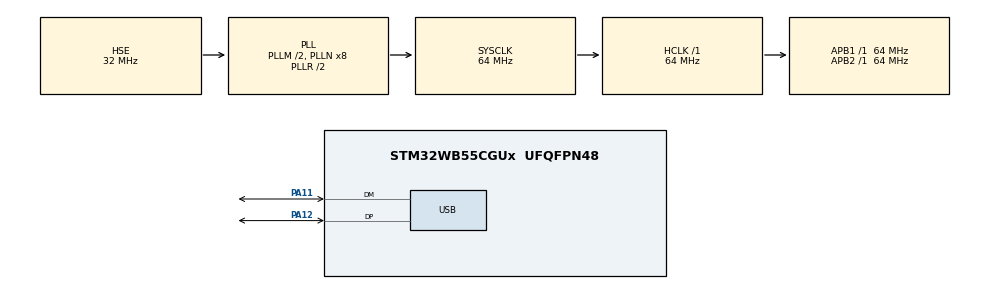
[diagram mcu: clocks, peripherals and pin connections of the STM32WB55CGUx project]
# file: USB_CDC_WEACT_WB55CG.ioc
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Mcu.Family=STM32WB
Mcu.Name=STM32WB55CGUx
Mcu.Package=UFQFPN48
NVIC.PriorityGroup=NVIC_PRIORITYGROUP_4
NVIC.USB_LP_IRQn=true\:0\:0\:false\:false\:true\:false\:true\:true
OSC_IN.Mode=HSE-External-Clock-Source
OSC_IN.Signal=RCC_OSC_IN
PA11.Mode=Device
PA11.Signal=USB_DM
PA12.Mode=Device
PA12.Signal=USB_DP
ProjectManager.HeapSize=0x200
ProjectManager.StackSize=0x400
ProjectManager.TargetToolchain=STM32CubeIDE
RCC.ADCFreq_Value=48000000
RCC.AHB2CLKDivider=RCC_SYSCLK_DIV2
RCC.AHBFreq_Value=64000000
RCC.APB1Freq_Value=64000000
RCC.APB1TimFreq_Value=64000000
RCC.APB2Freq_Value=64000000
RCC.APB2TimFreq_Value=64000000
RCC.APB3Freq_Value=16000000
RCC.CK48CLockSelection=RCC_USBCLKSOURCE_HSI48
RCC.Cortex2_Div=SYSTICK_CLKSOURCE_HCLK_DIV8
RCC.CortexFreq_Value=64000000
RCC.HCLKFreq_Value=64000000
RCC.HSE_VALUE=32000000
RCC.HSI48_VALUE=48000000
RCC.HSI_VALUE=16000000
RCC.LSE_VALUE=32768
RCC.PLLM=RCC_PLLM_DIV2
RCC.PLLSAI1N=6
RCC.PLLSourceVirtual=RCC_PLLSOURCE_HSE
RCC.SYSCLKFreq_VALUE=64000000
RCC.SYSCLKSource=RCC_SYSCLKSOURCE_PLLCLK
RCC.USBFreq_Value=48000000
RCC.VCOOutputFreq_Value=128000000
USB_DEVICE.CLASS_NAME_FS=CDC
USB_DEVICE.VirtualMode=Cdc
USB_DEVICE.VirtualModeFS=Cdc_FS
VP_MEMORYMAP_VS_MEMORYMAP.Mode=CurAppReg
VP_USB_DEVICE_VS_USB_DEVICE_CDC_FS.Mode=CDC_FS
board=custom

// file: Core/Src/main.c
/* USER CODE BEGIN Header */
/**
  ******************************************************************************
  * @file           : main.c
  * @brief          : Main program body
  ******************************************************************************
  * @attention
  *
  * Copyright (c) 2026 STMicroelectronics.
  * All rights reserved.
  *
  * This software is licensed under terms that can be found in the LICENSE file
  * in the root directory of this software component.
  * If no LICENSE file comes with this software, it is provided AS-IS.
  *
  ******************************************************************************
  */
/* USER CODE END Header */
#include "main.h"
#include "usb_device.h"

/* USER CODE BEGIN Includes */
#include "cdc_uart.h"
#include <stdio.h>
#include <string.h>
/* USER CODE END Includes */

/* USER CODE BEGIN PV */
CDC_HandleTypeDef hcdc;             /* user-visible ring-buffer state */
static char line_buf[128];  /* CDC_ReadLine fills this */
/* USER CODE END PV */

void SystemClock_Config(void);
void PeriphCommonClock_Config(void);
static void MX_GPIO_Init(void);

int main(void)
{

  /* MCU Configuration--------------------------------------------------------*/

  /* Reset of all peripherals, Initializes the Flash interface and the Systick. */
  HAL_Init();

  /* Configure the system clock */
  SystemClock_Config();

  /* Configure the peripherals common clocks */
  PeriphCommonClock_Config();

  /* Initialize all configured peripherals */
  MX_GPIO_Init();
  MX_USB_Device_Init();
  /* USER CODE BEGIN 2 */
  CDC_Init(&hcdc);
  /* USER CODE END 2 */

  /* Infinite loop */
  while (1)
  {

    /* USER CODE BEGIN 3 */

    /* --- Read one line at a time, then echo ------------------------- */
    if (CDC_ReadLine(&hcdc, line_buf, sizeof(line_buf)) == CDC_OK) {
      CDC_Printf(&hcdc, "Echo> %s\r\n", line_buf);
    }

    HAL_Delay(5);
  }
  /* USER CODE END 3 */
}

void SystemClock_Config(void)
{
  RCC_OscInitTypeDef RCC_OscInitStruct = {0};
  RCC_ClkInitTypeDef RCC_ClkInitStruct = {0};

  /** Configure the main internal regulator output voltage
  */
  __HAL_PWR_VOLTAGESCALING_CONFIG(PWR_REGULATOR_VOLTAGE_SCALE1);

  /** Initializes the RCC Oscillators according to the specified parameters
  * in the RCC_OscInitTypeDef structure.
  */
  RCC_OscInitStruct.OscillatorType = RCC_OSCILLATORTYPE_HSI48|RCC_OSCILLATORTYPE_HSI
                              |RCC_OSCILLATORTYPE_HSE;
  RCC_OscInitStruct.HSEState = RCC_HSE_ON;
  RCC_OscInitStruct.HSIState = RCC_HSI_ON;
  RCC_OscInitStruct.HSI48State = RCC_HSI48_ON;
  RCC_OscInitStruct.HSICalibrationValue = RCC_HSICALIBRATION_DEFAULT;
  RCC_OscInitStruct.PLL.PLLState = RCC_PLL_ON;
  RCC_OscInitStruct.PLL.PLLSource = RCC_PLLSOURCE_HSE;
  RCC_OscInitStruct.PLL.PLLM = RCC_PLLM_DIV2;
  RCC_OscInitStruct.PLL.PLLN = 8;
  RCC_OscInitStruct.PLL.PLLP = RCC_PLLP_DIV2;
  RCC_OscInitStruct.PLL.PLLR = RCC_PLLR_DIV2;
  RCC_OscInitStruct.PLL.PLLQ = RCC_PLLQ_DIV2;
  if (HAL_RCC_OscConfig(&RCC_OscInitStruct) != HAL_OK)
  {
    Error_Handler();
  }

  /** Configure the SYSCLKSource, HCLK, PCLK1 and PCLK2 clocks dividers
  */
  RCC_ClkInitStruct.ClockType = RCC_CLOCKTYPE_HCLK4|RCC_CLOCKTYPE_HCLK2
                              |RCC_CLOCKTYPE_HCLK|RCC_CLOCKTYPE_SYSCLK
                              |RCC_CLOCKTYPE_PCLK1|RCC_CLOCKTYPE_PCLK2;
  RCC_ClkInitStruct.SYSCLKSource = RCC_SYSCLKSOURCE_PLLCLK;
  RCC_ClkInitStruct.AHBCLKDivider = RCC_SYSCLK_DIV1;
  RCC_ClkInitStruct.APB1CLKDivider = RCC_HCLK_DIV1;
  RCC_ClkInitStruct.APB2CLKDivider = RCC_HCLK_DIV1;
  RCC_ClkInitStruct.AHBCLK2Divider = RCC_SYSCLK_DIV2;
  RCC_ClkInitStruct.AHBCLK4Divider = RCC_SYSCLK_DIV1;

  if (HAL_RCC_ClockConfig(&RCC_ClkInitStruct, FLASH_LATENCY_3) != HAL_OK)
  {
    Error_Handler();
  }
}

void PeriphCommonClock_Config(void)
{
  RCC_PeriphCLKInitTypeDef PeriphClkInitStruct = {0};

  /** Initializes the peripherals clock
  */
  PeriphClkInitStruct.PeriphClockSelection = RCC_PERIPHCLK_SMPS;
  PeriphClkInitStruct.SmpsClockSelection = RCC_SMPSCLKSOURCE_HSI;
  PeriphClkInitStruct.SmpsDivSelection = RCC_SMPSCLKDIV_RANGE1;

  if (HAL_RCCEx_PeriphCLKConfig(&PeriphClkInitStruct) != HAL_OK)
  {
    Error_Handler();
  }
}

static void MX_GPIO_Init(void)
{

  /* GPIO Ports Clock Enable */
  __HAL_RCC_GPIOA_CLK_ENABLE();

}

void Error_Handler(void)
{
  __disable_irq();
  while (1)
  {
  }
}
